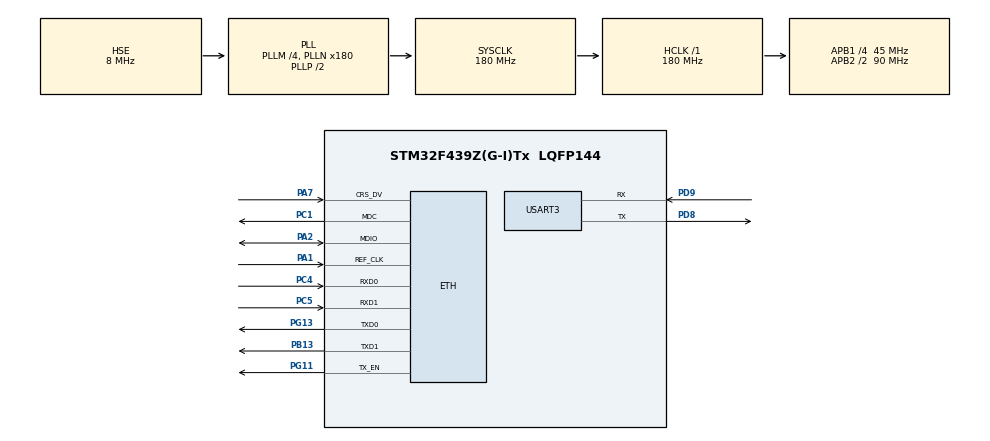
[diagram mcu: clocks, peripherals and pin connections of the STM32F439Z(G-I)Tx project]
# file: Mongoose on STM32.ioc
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ETH.MACAddr=80\:34\:28\:74\:A5\:CB
ETH.MediaInterface=HAL_ETH_RMII_MODE
FREERTOS.Tasks01=defaultTask,24,512,StartDefaultTask,Default,NULL,Dynamic,NULL,NULL
FREERTOS.configGENERATE_RUN_TIME_STATS=1
FREERTOS.configRECORD_STACK_HIGH_ADDRESS=1
FREERTOS.configUSE_NEWLIB_REENTRANT=1
Mcu.Family=STM32F4
Mcu.Name=STM32F439Z(G-I)Tx
Mcu.Package=LQFP144
NVIC.ETH_IRQn=true\:5\:0\:false\:false\:false\:true\:true\:false\:true
NVIC.PriorityGroup=NVIC_PRIORITYGROUP_4
NVIC.TIM6_DAC_IRQn=true\:15\:0\:false\:false\:true\:false\:false\:true\:true
NVIC.TimeBase=TIM6_DAC_IRQn
NVIC.TimeBaseIP=TIM6
PA1.Mode=RMII
PA1.Signal=ETH_REF_CLK
PA13.Mode=Serial_Wire
PA13.Signal=SYS_JTMS-SWDIO
PA14.Mode=Serial_Wire
PA14.Signal=SYS_JTCK-SWCLK
PA2.Mode=RMII
PA2.Signal=ETH_MDIO
PA7.Mode=RMII
PA7.Signal=ETH_CRS_DV
PB13.Mode=RMII
PB13.Signal=ETH_TXD1
PC1.Mode=RMII
PC1.Signal=ETH_MDC
PC14/OSC32_IN.Mode=LSE-External-Oscillator
PC14/OSC32_IN.Signal=RCC_OSC32_IN
PC15/OSC32_OUT.Mode=LSE-External-Oscillator
PC15/OSC32_OUT.Signal=RCC_OSC32_OUT
PC4.Mode=RMII
PC4.Signal=ETH_RXD0
PC5.Mode=RMII
PC5.Signal=ETH_RXD1
PD8.Mode=Asynchronous
PD8.Signal=USART3_TX
PD9.Mode=Asynchronous
PD9.Signal=USART3_RX
PG11.Mode=RMII
PG11.Signal=ETH_TX_EN
PG13.Mode=RMII
PG13.Signal=ETH_TXD0
PH0/OSC_IN.Mode=HSE-External-Clock-Source
PH0/OSC_IN.Signal=RCC_OSC_IN
PH1/OSC_OUT.Mode=HSE-External-Clock-Source
PH1/OSC_OUT.Signal=RCC_OSC_OUT
ProjectManager.HeapSize=0x200
ProjectManager.StackSize=0x400
ProjectManager.TargetToolchain=STM32CubeIDE
RCC.48MHZClocksFreq_Value=90000000
RCC.AHBFreq_Value=180000000
RCC.APB1CLKDivider=RCC_HCLK_DIV4
RCC.APB1Freq_Value=45000000
RCC.APB1TimFreq_Value=90000000
RCC.APB2CLKDivider=RCC_HCLK_DIV2
RCC.APB2Freq_Value=90000000
RCC.APB2TimFreq_Value=180000000
RCC.CortexFreq_Value=180000000
RCC.HCLKFreq_Value=180000000
RCC.HSE_VALUE=8000000
RCC.HSI_VALUE=16000000
RCC.PLLM=4
RCC.PLLN=180
RCC.PLLSourceVirtual=RCC_PLLSOURCE_HSE
RCC.SYSCLKFreq_VALUE=180000000
RCC.SYSCLKSource=RCC_SYSCLKSOURCE_PLLCLK
RCC.VCOOutputFreq_Value=360000000
USART3.VirtualMode=VM_ASYNC
VP_FREERTOS_VS_CMSIS_V2.Mode=CMSIS_V2
VP_SYS_VS_tim6.Mode=TIM6
board=custom

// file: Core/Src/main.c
/* USER CODE BEGIN Header */
/**
  ******************************************************************************
  * @file           : main.c
  * @brief          : Main program body
  ******************************************************************************
  * @attention
  *
  * Copyright (c) 2025 STMicroelectronics.
  * All rights reserved.
  *
  * This software is licensed under terms that can be found in the LICENSE file
  * in the root directory of this software component.
  * If no LICENSE file comes with this software, it is provided AS-IS.
  *
  ******************************************************************************
  */
/* USER CODE END Header */
#include "main.h"
#include "string.h"
#include "cmsis_os.h"

/* USER CODE BEGIN Includes */
#include "mongoose.h"
/* USER CODE END Includes */

ETH_TxPacketConfig TxConfig;
ETH_DMADescTypeDef  DMARxDscrTab[ETH_RX_DESC_CNT]; /* Ethernet Rx DMA Descriptors */
ETH_DMADescTypeDef  DMATxDscrTab[ETH_TX_DESC_CNT]; /* Ethernet Tx DMA Descriptors */

ETH_HandleTypeDef heth;

UART_HandleTypeDef huart3;

/* Definitions for defaultTask */
osThreadId_t defaultTaskHandle;
const osThreadAttr_t defaultTask_attributes = {
  .name = "defaultTask",
  .stack_size = 512 * 4,
  .priority = (osPriority_t) osPriorityNormal,
};

void SystemClock_Config(void);
static void MX_GPIO_Init(void);
static void MX_ETH_Init(void);
static void MX_USART3_UART_Init(void);
void StartDefaultTask(void *argument);

int main(void)
{

  /* MCU Configuration--------------------------------------------------------*/

  /* Reset of all peripherals, Initializes the Flash interface and the Systick. */
  HAL_Init();

  /* Configure the system clock */
  SystemClock_Config();

  /* Initialize all configured peripherals */
  MX_GPIO_Init();
  MX_ETH_Init();
  MX_USART3_UART_Init();

  /* Init scheduler */
  osKernelInitialize();

  /* Create the thread(s) */
  /* creation of defaultTask */
  defaultTaskHandle = osThreadNew(StartDefaultTask, NULL, &defaultTask_attributes);

  /* Start scheduler */
  osKernelStart();

  /* We should never get here as control is now taken by the scheduler */

  /* Infinite loop */
  while (1)
  {

  }
}

void SystemClock_Config(void)
{
  RCC_OscInitTypeDef RCC_OscInitStruct = {0};
  RCC_ClkInitTypeDef RCC_ClkInitStruct = {0};

  /** Configure the main internal regulator output voltage
  */
  __HAL_RCC_PWR_CLK_ENABLE();
  __HAL_PWR_VOLTAGESCALING_CONFIG(PWR_REGULATOR_VOLTAGE_SCALE1);

  /** Initializes the RCC Oscillators according to the specified parameters
  * in the RCC_OscInitTypeDef structure.
  */
  RCC_OscInitStruct.OscillatorType = RCC_OSCILLATORTYPE_HSE;
  RCC_OscInitStruct.HSEState = RCC_HSE_BYPASS;
  RCC_OscInitStruct.PLL.PLLState = RCC_PLL_ON;
  RCC_OscInitStruct.PLL.PLLSource = RCC_PLLSOURCE_HSE;
  RCC_OscInitStruct.PLL.PLLM = 4;
  RCC_OscInitStruct.PLL.PLLN = 180;
  RCC_OscInitStruct.PLL.PLLP = RCC_PLLP_DIV2;
  RCC_OscInitStruct.PLL.PLLQ = 4;
  if (HAL_RCC_OscConfig(&RCC_OscInitStruct) != HAL_OK)
  {
    Error_Handler();
  }

  /** Activate the Over-Drive mode
  */
  if (HAL_PWREx_EnableOverDrive() != HAL_OK)
  {
    Error_Handler();
  }

  /** Initializes the CPU, AHB and APB buses clocks
  */
  RCC_ClkInitStruct.ClockType = RCC_CLOCKTYPE_HCLK|RCC_CLOCKTYPE_SYSCLK
                              |RCC_CLOCKTYPE_PCLK1|RCC_CLOCKTYPE_PCLK2;
  RCC_ClkInitStruct.SYSCLKSource = RCC_SYSCLKSOURCE_PLLCLK;
  RCC_ClkInitStruct.AHBCLKDivider = RCC_SYSCLK_DIV1;
  RCC_ClkInitStruct.APB1CLKDivider = RCC_HCLK_DIV4;
  RCC_ClkInitStruct.APB2CLKDivider = RCC_HCLK_DIV2;

  if (HAL_RCC_ClockConfig(&RCC_ClkInitStruct, FLASH_LATENCY_5) != HAL_OK)
  {
    Error_Handler();
  }
}

static void MX_ETH_Init(void)
{

   static uint8_t MACAddr[6];

  heth.Instance = ETH;
  MACAddr[0] = 0x80;
  MACAddr[1] = 0x34;
  MACAddr[2] = 0x28;
  MACAddr[3] = 0x74;
  MACAddr[4] = 0xA5;
  MACAddr[5] = 0xCB;
  heth.Init.MACAddr = &MACAddr[0];
  heth.Init.MediaInterface = HAL_ETH_RMII_MODE;
  heth.Init.TxDesc = DMATxDscrTab;
  heth.Init.RxDesc = DMARxDscrTab;
  heth.Init.RxBuffLen = 1524;

  if (HAL_ETH_Init(&heth) != HAL_OK)
  {
    Error_Handler();
  }

  memset(&TxConfig, 0 , sizeof(ETH_TxPacketConfig));
  TxConfig.Attributes = ETH_TX_PACKETS_FEATURES_CSUM | ETH_TX_PACKETS_FEATURES_CRCPAD;
  TxConfig.ChecksumCtrl = ETH_CHECKSUM_IPHDR_PAYLOAD_INSERT_PHDR_CALC;
  TxConfig.CRCPadCtrl = ETH_CRC_PAD_INSERT;

}

static void MX_USART3_UART_Init(void)
{

  huart3.Instance = USART3;
  huart3.Init.BaudRate = 115200;
  huart3.Init.WordLength = UART_WORDLENGTH_8B;
  huart3.Init.StopBits = UART_STOPBITS_1;
  huart3.Init.Parity = UART_PARITY_NONE;
  huart3.Init.Mode = UART_MODE_TX_RX;
  huart3.Init.HwFlowCtl = UART_HWCONTROL_NONE;
  huart3.Init.OverSampling = UART_OVERSAMPLING_16;
  if (HAL_UART_Init(&huart3) != HAL_OK)
  {
    Error_Handler();
  }

}

static void MX_GPIO_Init(void)
{

  /* GPIO Ports Clock Enable */
  __HAL_RCC_GPIOC_CLK_ENABLE();
  __HAL_RCC_GPIOH_CLK_ENABLE();
  __HAL_RCC_GPIOA_CLK_ENABLE();
  __HAL_RCC_GPIOB_CLK_ENABLE();
  __HAL_RCC_GPIOD_CLK_ENABLE();
  __HAL_RCC_GPIOG_CLK_ENABLE();

}

/* USER CODE BEGIN 4 */

static void fn(struct mg_connection *c, int ev, void *ev_data) {
  if (ev == MG_EV_HTTP_MSG) {
    mg_http_reply(c, 200, "Content-Type: text/plain\r\n", "Hello, %s\n", "world");
  }
}

void log_fn(char ch, void *param){
	HAL_UART_Transmit(&huart3, (uint8_t*)&ch, 1, 1);
}
/* USER CODE END 4 */

void StartDefaultTask(void *argument)
{
  /* USER CODE BEGIN 5 */
	struct mg_mgr mgr;
	mg_log_set(MG_LL_DEBUG);
	mg_log_set_fn(log_fn, NULL);
	mg_mgr_init(&mgr);
	mg_http_listen(&mgr, "http://0.0.0.0:8000", fn, NULL);
  /* Infinite loop */
  for(;;)
  {
	  mg_mgr_poll(&mgr, 1000);
  }
  /* USER CODE END 5 */
}

void HAL_TIM_PeriodElapsedCallback(TIM_HandleTypeDef *htim)
{
  if (htim->Instance == TIM6) {
    HAL_IncTick();
  }
}

void Error_Handler(void)
{
  __disable_irq();
  while (1)
  {
  }
}
